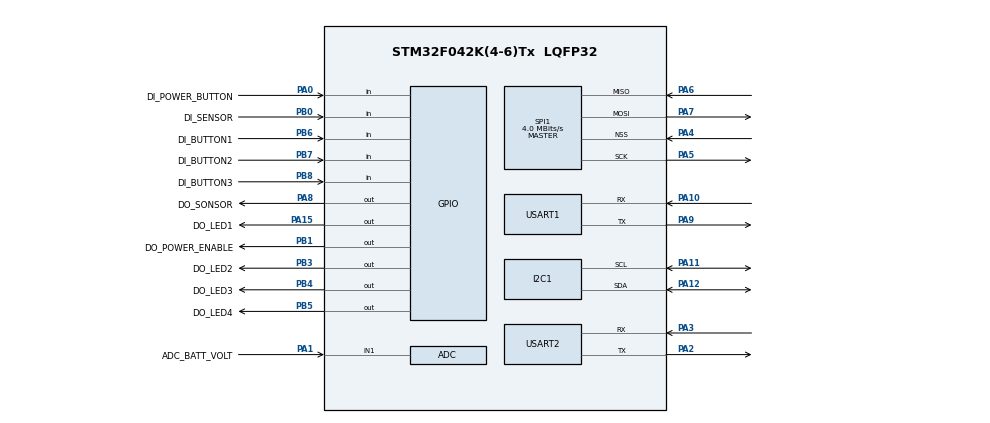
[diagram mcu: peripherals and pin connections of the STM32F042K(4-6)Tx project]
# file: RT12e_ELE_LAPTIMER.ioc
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Mcu.Family=STM32F0
PA6.Mode=Full_Duplex_Master
PA7.Mode=Full_Duplex_Master
PA10.Mode=Asynchronous
SPI1.VirtualType=VM_MASTER
PA0.GPIO_Label=DI_POWER_BUTTON
PA11.Mode=I2C
PB0.GPIO_Label=DI_SENSOR
PB6.GPIO_Label=DI_BUTTON1
ProjectManager.StackSize=0x400
USART1.VirtualMode-Asynchronous=VM_ASYNC
PA3.Mode=Asynchronous
PA13.Signal=SYS_SWDIO
PB8.GPIO_Label=DI_BUTTON3
PA15.GPIO_Label=DO_LED1
PA9.Mode=Asynchronous
PA12.Signal=I2C1_SDA
PA8.GPIO_Label=DO_SONSOR
PA4.Mode=NSS_Signal_Hard_Input
ProjectManager.TargetToolchain=SW4STM32
SPI1.Direction=SPI_DIRECTION_2LINES
PA9.Signal=USART1_TX
PB6.Signal=GPIO_Input
SPI1.CalculateBaudRate=4.0 MBits/s
PA1.Signal=SharedAnalog_PA1
PA5.Signal=SPI1_SCK
board=custom
USART2.VirtualMode-Asynchronous=VM_ASYNC
PB4.GPIO_Label=DO_LED3
SPI1.Mode=SPI_MODE_MASTER
PA14.Mode=Serial_Wire
PB1.GPIO_Label=DO_POWER_ENABLE
PA1.GPIO_Label=ADC_BATT_VOLT
PB7.Signal=GPIO_Input
PA8.Signal=GPIO_Output
SPI1.VirtualNSS=VM_NSSHARD
PA13.Mode=Serial_Wire
Mcu.Name=STM32F042K(4-6)Tx
PA2.Signal=USART2_TX
PA0.Signal=GPIO_Input
PB7.GPIO_Label=DI_BUTTON2
PB3.Signal=GPIO_Output
PA4.Signal=SPI1_NSS
Mcu.Package=LQFP32
PB5.Signal=GPIO_Output
PA6.Signal=SPI1_MISO
PB1.Signal=GPIO_Output
PA12.Mode=I2C
PA11.Signal=I2C1_SCL
PA10.Signal=USART1_RX
PA14.Signal=SYS_SWCLK
PA15.Signal=GPIO_Output
ProjectManager.HeapSize=0x200
SH.SharedAnalog_PA1.1=ADC_IN1,IN1
SH.SharedAnalog_PA1.0=GPIO_Analog
PB5.GPIO_Label=DO_LED4
PA2.Mode=Asynchronous
PB8.Signal=GPIO_Input
PB0.Signal=GPIO_Input
PB4.Signal=GPIO_Output
PA3.Signal=USART2_RX
PA7.Signal=SPI1_MOSI
PA5.Mode=Full_Duplex_Master
PB3.GPIO_Label=DO_LED2

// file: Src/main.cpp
/* USER CODE BEGIN Header */
/**
  ******************************************************************************
  * @file           : main.c
  * @brief          : Main program body
  ******************************************************************************
  * @attention
  *
  * <h2><center>&copy; Copyright (c) 2020 STMicroelectronics.
  * All rights reserved.</center></h2>
  *
  * This software component is licensed by ST under BSD 3-Clause license,
  * the "License"; You may not use this file except in compliance with the
  * License. You may obtain a copy of the License at:
  *                        opensource.org/licenses/BSD-3-Clause
  *
  ******************************************************************************
  */
/* USER CODE END Header */
#include "main.h"

/* USER CODE BEGIN Includes */
#include "Transmitter.h"
#include "Timer.h"
#include "string.h"
/* USER CODE END Includes */

ADC_HandleTypeDef hadc;

I2C_HandleTypeDef hi2c1;

SPI_HandleTypeDef hspi1;

UART_HandleTypeDef huart1;
UART_HandleTypeDef huart2;

void SystemClock_Config(void);
static void MX_GPIO_Init(void);
static void MX_ADC_Init(void);
static void MX_I2C1_Init(void);
static void MX_SPI1_Init(void);
static void MX_USART1_UART_Init(void);
static void MX_USART2_UART_Init(void);

int main(void)
{

  /* MCU Configuration--------------------------------------------------------*/

  /* Reset of all peripherals, Initializes the Flash interface and the Systick. */
  HAL_Init();

  /* Configure the system clock */
  SystemClock_Config();

  /* Initialize all configured peripherals */
  MX_GPIO_Init();
  MX_ADC_Init();
  MX_I2C1_Init();
  MX_SPI1_Init();
  MX_USART1_UART_Init();
  MX_USART2_UART_Init();
  /* USER CODE BEGIN 2 */

  Transmitter trans(&huart2);
  Timer timer();

  HAL_GPIO_WritePin(DO_LED1_GPIO_Port, DO_LED1_Pin, GPIO_PIN_SET);
  HAL_GPIO_WritePin(DO_POWER_ENABLE_GPIO_Port, DO_POWER_ENABLE_Pin, GPIO_PIN_SET);

  bool pinPowerEnabledClicked = true;

  /* USER CODE END 2 */

  /* Infinite loop */
  /* USER CODE BEGIN WHILE */
  while (1)
  {

	  unsigned char ch = '3';

	    HAL_UART_Transmit(&huart2, &ch, 1, 0xFFFF);
    /* USER CODE END WHILE */
	  if(HAL_GPIO_ReadPin(DI_POWER_BUTTON_GPIO_Port, DI_POWER_BUTTON_Pin) == GPIO_PIN_SET and !pinPowerEnabledClicked)
	  {
		  HAL_GPIO_WritePin(DO_POWER_ENABLE_GPIO_Port, DO_POWER_ENABLE_Pin, GPIO_PIN_RESET);

	  }
	  if(HAL_GPIO_ReadPin(DI_POWER_BUTTON_GPIO_Port, DI_POWER_BUTTON_Pin) == GPIO_PIN_RESET)
	  {
		  pinPowerEnabledClicked = false;
	  }
  }
}

void SystemClock_Config(void)
{
  RCC_OscInitTypeDef RCC_OscInitStruct = {0};
  RCC_ClkInitTypeDef RCC_ClkInitStruct = {0};
  RCC_PeriphCLKInitTypeDef PeriphClkInit = {0};

  /** Initializes the RCC Oscillators according to the specified parameters
  * in the RCC_OscInitTypeDef structure.
  */
  RCC_OscInitStruct.OscillatorType = RCC_OSCILLATORTYPE_HSI|RCC_OSCILLATORTYPE_HSI14;
  RCC_OscInitStruct.HSIState = RCC_HSI_ON;
  RCC_OscInitStruct.HSI14State = RCC_HSI14_ON;
  RCC_OscInitStruct.HSICalibrationValue = RCC_HSICALIBRATION_DEFAULT;
  RCC_OscInitStruct.HSI14CalibrationValue = 16;
  RCC_OscInitStruct.PLL.PLLState = RCC_PLL_NONE;
  if (HAL_RCC_OscConfig(&RCC_OscInitStruct) != HAL_OK)
  {
    Error_Handler();
  }
  /** Initializes the CPU, AHB and APB buses clocks
  */
  RCC_ClkInitStruct.ClockType = RCC_CLOCKTYPE_HCLK|RCC_CLOCKTYPE_SYSCLK
                              |RCC_CLOCKTYPE_PCLK1;
  RCC_ClkInitStruct.SYSCLKSource = RCC_SYSCLKSOURCE_HSI;
  RCC_ClkInitStruct.AHBCLKDivider = RCC_SYSCLK_DIV1;
  RCC_ClkInitStruct.APB1CLKDivider = RCC_HCLK_DIV1;

  if (HAL_RCC_ClockConfig(&RCC_ClkInitStruct, FLASH_LATENCY_0) != HAL_OK)
  {
    Error_Handler();
  }
  PeriphClkInit.PeriphClockSelection = RCC_PERIPHCLK_USART1|RCC_PERIPHCLK_I2C1;
  PeriphClkInit.Usart1ClockSelection = RCC_USART1CLKSOURCE_PCLK1;
  PeriphClkInit.I2c1ClockSelection = RCC_I2C1CLKSOURCE_HSI;
  if (HAL_RCCEx_PeriphCLKConfig(&PeriphClkInit) != HAL_OK)
  {
    Error_Handler();
  }
}

static void MX_ADC_Init(void)
{

  ADC_ChannelConfTypeDef sConfig = {0};

  /** Configure the global features of the ADC (Clock, Resolution, Data Alignment and number of conversion)
  */
  hadc.Instance = ADC1;
  hadc.Init.ClockPrescaler = ADC_CLOCK_ASYNC_DIV1;
  hadc.Init.Resolution = ADC_RESOLUTION_12B;
  hadc.Init.DataAlign = ADC_DATAALIGN_RIGHT;
  hadc.Init.ScanConvMode = ADC_SCAN_DIRECTION_FORWARD;
  hadc.Init.EOCSelection = ADC_EOC_SINGLE_CONV;
  hadc.Init.LowPowerAutoWait = DISABLE;
  hadc.Init.LowPowerAutoPowerOff = DISABLE;
  hadc.Init.ContinuousConvMode = DISABLE;
  hadc.Init.DiscontinuousConvMode = DISABLE;
  hadc.Init.ExternalTrigConv = ADC_SOFTWARE_START;
  hadc.Init.ExternalTrigConvEdge = ADC_EXTERNALTRIGCONVEDGE_NONE;
  hadc.Init.DMAContinuousRequests = DISABLE;
  hadc.Init.Overrun = ADC_OVR_DATA_PRESERVED;
  if (HAL_ADC_Init(&hadc) != HAL_OK)
  {
    Error_Handler();
  }
  /** Configure for the selected ADC regular channel to be converted.
  */
  sConfig.Channel = ADC_CHANNEL_1;
  sConfig.Rank = ADC_RANK_CHANNEL_NUMBER;
  sConfig.SamplingTime = ADC_SAMPLETIME_1CYCLE_5;
  if (HAL_ADC_ConfigChannel(&hadc, &sConfig) != HAL_OK)
  {
    Error_Handler();
  }

}

static void MX_I2C1_Init(void)
{

  hi2c1.Instance = I2C1;
  hi2c1.Init.Timing = 0x2000090E;
  hi2c1.Init.OwnAddress1 = 0;
  hi2c1.Init.AddressingMode = I2C_ADDRESSINGMODE_7BIT;
  hi2c1.Init.DualAddressMode = I2C_DUALADDRESS_DISABLE;
  hi2c1.Init.OwnAddress2 = 0;
  hi2c1.Init.OwnAddress2Masks = I2C_OA2_NOMASK;
  hi2c1.Init.GeneralCallMode = I2C_GENERALCALL_DISABLE;
  hi2c1.Init.NoStretchMode = I2C_NOSTRETCH_DISABLE;
  if (HAL_I2C_Init(&hi2c1) != HAL_OK)
  {
    Error_Handler();
  }
  /** Configure Analogue filter
  */
  if (HAL_I2CEx_ConfigAnalogFilter(&hi2c1, I2C_ANALOGFILTER_ENABLE) != HAL_OK)
  {
    Error_Handler();
  }
  /** Configure Digital filter
  */
  if (HAL_I2CEx_ConfigDigitalFilter(&hi2c1, 0) != HAL_OK)
  {
    Error_Handler();
  }

}

static void MX_SPI1_Init(void)
{

  /* SPI1 parameter configuration*/
  hspi1.Instance = SPI1;
  hspi1.Init.Mode = SPI_MODE_MASTER;
  hspi1.Init.Direction = SPI_DIRECTION_2LINES;
  hspi1.Init.DataSize = SPI_DATASIZE_4BIT;
  hspi1.Init.CLKPolarity = SPI_POLARITY_LOW;
  hspi1.Init.CLKPhase = SPI_PHASE_1EDGE;
  hspi1.Init.NSS = SPI_NSS_HARD_INPUT;
  hspi1.Init.BaudRatePrescaler = SPI_BAUDRATEPRESCALER_2;
  hspi1.Init.FirstBit = SPI_FIRSTBIT_MSB;
  hspi1.Init.TIMode = SPI_TIMODE_DISABLE;
  hspi1.Init.CRCCalculation = SPI_CRCCALCULATION_DISABLE;
  hspi1.Init.CRCPolynomial = 7;
  hspi1.Init.CRCLength = SPI_CRC_LENGTH_DATASIZE;
  hspi1.Init.NSSPMode = SPI_NSS_PULSE_ENABLE;
  if (HAL_SPI_Init(&hspi1) != HAL_OK)
  {
    Error_Handler();
  }

}

static void MX_USART1_UART_Init(void)
{

  huart1.Instance = USART1;
  huart1.Init.BaudRate = 38400;
  huart1.Init.WordLength = UART_WORDLENGTH_8B;
  huart1.Init.StopBits = UART_STOPBITS_1;
  huart1.Init.Parity = UART_PARITY_NONE;
  huart1.Init.Mode = UART_MODE_TX_RX;
  huart1.Init.HwFlowCtl = UART_HWCONTROL_NONE;
  huart1.Init.OverSampling = UART_OVERSAMPLING_16;
  huart1.Init.OneBitSampling = UART_ONE_BIT_SAMPLE_DISABLE;
  huart1.AdvancedInit.AdvFeatureInit = UART_ADVFEATURE_NO_INIT;
  if (HAL_UART_Init(&huart1) != HAL_OK)
  {
    Error_Handler();
  }

}

static void MX_USART2_UART_Init(void)
{

  huart2.Instance = USART2;
  huart2.Init.BaudRate = 38400;
  huart2.Init.WordLength = UART_WORDLENGTH_8B;
  huart2.Init.StopBits = UART_STOPBITS_1;
  huart2.Init.Parity = UART_PARITY_NONE;
  huart2.Init.Mode = UART_MODE_TX_RX;
  huart2.Init.HwFlowCtl = UART_HWCONTROL_NONE;
  huart2.Init.OverSampling = UART_OVERSAMPLING_16;
  huart2.Init.OneBitSampling = UART_ONE_BIT_SAMPLE_DISABLE;
  huart2.AdvancedInit.AdvFeatureInit = UART_ADVFEATURE_NO_INIT;
  if (HAL_UART_Init(&huart2) != HAL_OK)
  {
    Error_Handler();
  }

}

static void MX_GPIO_Init(void)
{
  GPIO_InitTypeDef GPIO_InitStruct = {0};

  /* GPIO Ports Clock Enable */
  __HAL_RCC_GPIOA_CLK_ENABLE();
  __HAL_RCC_GPIOB_CLK_ENABLE();

  /*Configure GPIO pin Output Level */
  HAL_GPIO_WritePin(GPIOB, DO_POWER_ENABLE_Pin|DO_LED2_Pin|DO_LED3_Pin|DO_LED4_Pin, GPIO_PIN_RESET);

  /*Configure GPIO pin Output Level */
  HAL_GPIO_WritePin(GPIOA, DO_SONSOR_Pin|DO_LED1_Pin, GPIO_PIN_RESET);

  /*Configure GPIO pin : DI_POWER_BUTTON_Pin */
  GPIO_InitStruct.Pin = DI_POWER_BUTTON_Pin;
  GPIO_InitStruct.Mode = GPIO_MODE_INPUT;
  GPIO_InitStruct.Pull = GPIO_NOPULL;
  HAL_GPIO_Init(DI_POWER_BUTTON_GPIO_Port, &GPIO_InitStruct);

  /*Configure GPIO pins : DI_SENSOR_Pin DI_BUTTON1_Pin DI_BUTTON2_Pin DI_BUTTON3_Pin */
  GPIO_InitStruct.Pin = DI_SENSOR_Pin|DI_BUTTON1_Pin|DI_BUTTON2_Pin|DI_BUTTON3_Pin;
  GPIO_InitStruct.Mode = GPIO_MODE_INPUT;
  GPIO_InitStruct.Pull = GPIO_NOPULL;
  HAL_GPIO_Init(GPIOB, &GPIO_InitStruct);

  /*Configure GPIO pins : DO_POWER_ENABLE_Pin DO_LED2_Pin DO_LED3_Pin DO_LED4_Pin */
  GPIO_InitStruct.Pin = DO_POWER_ENABLE_Pin|DO_LED2_Pin|DO_LED3_Pin|DO_LED4_Pin;
  GPIO_InitStruct.Mode = GPIO_MODE_OUTPUT_PP;
  GPIO_InitStruct.Pull = GPIO_NOPULL;
  GPIO_InitStruct.Speed = GPIO_SPEED_FREQ_LOW;
  HAL_GPIO_Init(GPIOB, &GPIO_InitStruct);

  /*Configure GPIO pins : DO_SONSOR_Pin DO_LED1_Pin */
  GPIO_InitStruct.Pin = DO_SONSOR_Pin|DO_LED1_Pin;
  GPIO_InitStruct.Mode = GPIO_MODE_OUTPUT_PP;
  GPIO_InitStruct.Pull = GPIO_NOPULL;
  GPIO_InitStruct.Speed = GPIO_SPEED_FREQ_LOW;
  HAL_GPIO_Init(GPIOA, &GPIO_InitStruct);

}

void Error_Handler(void)
{
  __disable_irq();
  while (1)
  {
  }
}

/************************ (C) COPYRIGHT STMicroelectronics *****END OF FILE****/
